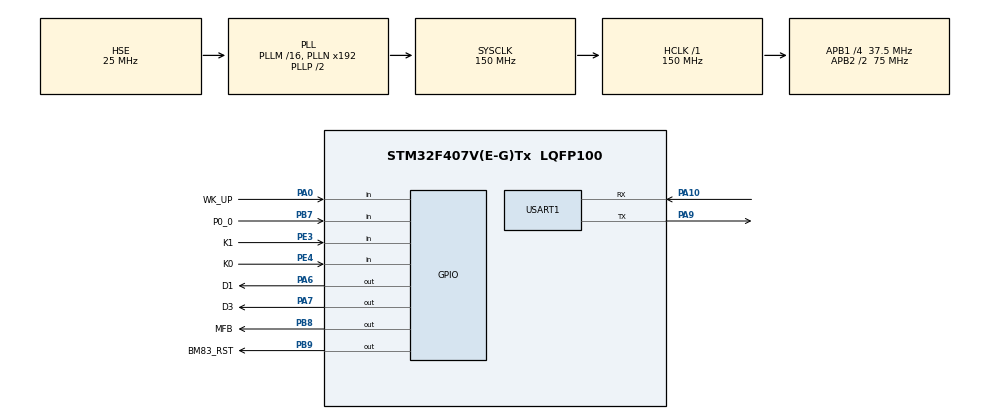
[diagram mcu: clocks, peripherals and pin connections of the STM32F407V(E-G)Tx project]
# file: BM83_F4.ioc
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Mcu.Family=STM32F4
Mcu.Name=STM32F407V(E-G)Tx
Mcu.Package=LQFP100
NVIC.PriorityGroup=NVIC_PRIORITYGROUP_4
NVIC.USART1_IRQn=true\:0\:0\:false\:false\:true\:true\:true\:true
PA0-WKUP.GPIO_Label=WK_UP
PA0-WKUP.Signal=GPIO_Input
PA10.Mode=Asynchronous
PA10.Signal=USART1_RX
PA13.Mode=JTAG_5_pins
PA13.Signal=SYS_JTMS-SWDIO
PA14.Mode=JTAG_5_pins
PA14.Signal=SYS_JTCK-SWCLK
PA15.Mode=JTAG_5_pins
PA15.Signal=SYS_JTDI
PA6.GPIO_Label=D1
PA6.Signal=GPIO_Output
PA7.GPIO_Label=D3
PA7.Signal=GPIO_Output
PA9.Mode=Asynchronous
PA9.Signal=USART1_TX
PB3.Mode=JTAG_5_pins
PB3.Signal=SYS_JTDO-SWO
PB4.Mode=JTAG_5_pins
PB4.Signal=SYS_JTRST
PB7.GPIO_Label=P0_0
PB7.Signal=GPIO_Input
PB8.GPIO_Label=MFB
PB8.Signal=GPIO_Output
PB9.GPIO_Label=BM83_RST
PB9.Signal=GPIO_Output
PC14-OSC32_IN.Mode=LSE-External-Oscillator
PC14-OSC32_IN.Signal=RCC_OSC32_IN
PC15-OSC32_OUT.Mode=LSE-External-Oscillator
PC15-OSC32_OUT.Signal=RCC_OSC32_OUT
PE3.GPIO_Label=K1
PE3.Signal=GPIO_Input
PE4.GPIO_Label=K0
PE4.Signal=GPIO_Input
PH0-OSC_IN.Mode=HSE-External-Oscillator
PH0-OSC_IN.Signal=RCC_OSC_IN
PH1-OSC_OUT.Mode=HSE-External-Oscillator
PH1-OSC_OUT.Signal=RCC_OSC_OUT
ProjectManager.HeapSize=0x200
ProjectManager.StackSize=0x400
ProjectManager.TargetToolchain=Makefile
RCC.48MHZClocksFreq_Value=75000000
RCC.AHBFreq_Value=150000000
RCC.APB1CLKDivider=RCC_HCLK_DIV4
RCC.APB1Freq_Value=37500000
RCC.APB1TimFreq_Value=75000000
RCC.APB2CLKDivider=RCC_HCLK_DIV2
RCC.APB2Freq_Value=75000000
RCC.APB2TimFreq_Value=150000000
RCC.CortexFreq_Value=150000000
RCC.HCLKFreq_Value=150000000
RCC.HSE_VALUE=25000000
RCC.HSI_VALUE=16000000
RCC.PLLSourceVirtual=RCC_PLLSOURCE_HSE
RCC.SYSCLKFreq_VALUE=150000000
RCC.SYSCLKSource=RCC_SYSCLKSOURCE_PLLCLK
RCC.VCOOutputFreq_Value=300000000
USART1.VirtualMode=VM_ASYNC
board=custom

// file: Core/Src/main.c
/* USER CODE BEGIN Header */
/**
  ******************************************************************************
  * @file           : main.c
  * @brief          : Main program body
  ******************************************************************************
  * @attention
  *
  * Copyright (c) 2024 STMicroelectronics.
  * All rights reserved.
  *
  * This software is licensed under terms that can be found in the LICENSE file
  * in the root directory of this software component.
  * If no LICENSE file comes with this software, it is provided AS-IS.
  *
  ******************************************************************************
  */
/* USER CODE END Header */
#include "main.h"
#include "app.h"
#include "app.c"

UART_HandleTypeDef huart1;

void SystemClock_Config(void);
static void MX_GPIO_Init(void);
static void MX_USART1_UART_Init(void);

int main(void)
{

  /* MCU Configuration--------------------------------------------------------*/

  /* Reset of all peripherals, Initializes the Flash interface and the Systick. */
  HAL_Init();

  /* Configure the system clock */
  SystemClock_Config();

  /* Initialize all configured peripherals */
  MX_GPIO_Init();
  MX_USART1_UART_Init();

  /* USER CODE BEGIN 2 */
  /*Initialize Bluetooth controller*/
  APP_Initialize();

  /* USER CODE END 2 */

  /* Infinite loop */
  while (1)
  {

  }
}

void SystemClock_Config(void)
{
  RCC_OscInitTypeDef RCC_OscInitStruct = {0};
  RCC_ClkInitTypeDef RCC_ClkInitStruct = {0};

  /** Configure the main internal regulator output voltage
  */
  __HAL_RCC_PWR_CLK_ENABLE();
  __HAL_PWR_VOLTAGESCALING_CONFIG(PWR_REGULATOR_VOLTAGE_SCALE1);

  /** Initializes the RCC Oscillators according to the specified parameters
  * in the RCC_OscInitTypeDef structure.
  */
  RCC_OscInitStruct.OscillatorType = RCC_OSCILLATORTYPE_HSE;
  RCC_OscInitStruct.HSEState = RCC_HSE_ON;
  RCC_OscInitStruct.PLL.PLLState = RCC_PLL_ON;
  RCC_OscInitStruct.PLL.PLLSource = RCC_PLLSOURCE_HSE;
  RCC_OscInitStruct.PLL.PLLM = 16;
  RCC_OscInitStruct.PLL.PLLN = 192;
  RCC_OscInitStruct.PLL.PLLP = RCC_PLLP_DIV2;
  RCC_OscInitStruct.PLL.PLLQ = 4;
  if (HAL_RCC_OscConfig(&RCC_OscInitStruct) != HAL_OK)
  {
    Error_Handler();
  }

  /** Initializes the CPU, AHB and APB buses clocks
  */
  RCC_ClkInitStruct.ClockType = RCC_CLOCKTYPE_HCLK|RCC_CLOCKTYPE_SYSCLK
                              |RCC_CLOCKTYPE_PCLK1|RCC_CLOCKTYPE_PCLK2;
  RCC_ClkInitStruct.SYSCLKSource = RCC_SYSCLKSOURCE_PLLCLK;
  RCC_ClkInitStruct.AHBCLKDivider = RCC_SYSCLK_DIV1;
  RCC_ClkInitStruct.APB1CLKDivider = RCC_HCLK_DIV4;
  RCC_ClkInitStruct.APB2CLKDivider = RCC_HCLK_DIV2;

  if (HAL_RCC_ClockConfig(&RCC_ClkInitStruct, FLASH_LATENCY_4) != HAL_OK)
  {
    Error_Handler();
  }
}

static void MX_USART1_UART_Init(void)
{

  /* USER CODE BEGIN USART1_Init 0 */
  // Enable one-bit sample method
  __HAL_UART_ONE_BIT_SAMPLE_ENABLE(&huart1);

  /* USER CODE END USART1_Init 0 */

  huart1.Instance = USART1;
  huart1.Init.BaudRate = 115200;
  huart1.Init.WordLength = UART_WORDLENGTH_8B;
  huart1.Init.StopBits = UART_STOPBITS_1;
  huart1.Init.Parity = UART_PARITY_NONE;
  huart1.Init.Mode = UART_MODE_TX_RX;
  huart1.Init.HwFlowCtl = UART_HWCONTROL_NONE;
  huart1.Init.OverSampling = UART_OVERSAMPLING_16;
  if (HAL_UART_Init(&huart1) != HAL_OK)
  {
    Error_Handler();
  }

}

static void MX_GPIO_Init(void)
{
  GPIO_InitTypeDef GPIO_InitStruct = {0};

  /* GPIO Ports Clock Enable */
  __HAL_RCC_GPIOE_CLK_ENABLE();
  __HAL_RCC_GPIOC_CLK_ENABLE();
  __HAL_RCC_GPIOH_CLK_ENABLE();
  __HAL_RCC_GPIOA_CLK_ENABLE();
  __HAL_RCC_GPIOB_CLK_ENABLE();

  /*Configure GPIO pin Output Level */
  HAL_GPIO_WritePin(GPIOA, D1_Pin|D3_Pin, GPIO_PIN_RESET);

  /*Configure GPIO pin Output Level */
  HAL_GPIO_WritePin(GPIOB, MFB_Pin|BM83_RST_Pin, GPIO_PIN_RESET);

  /*Configure GPIO pins : K1_Pin K0_Pin */
  GPIO_InitStruct.Pin = K1_Pin|K0_Pin;
  GPIO_InitStruct.Mode = GPIO_MODE_INPUT;
  GPIO_InitStruct.Pull = GPIO_NOPULL;
  HAL_GPIO_Init(GPIOE, &GPIO_InitStruct);

  /*Configure GPIO pin : WK_UP_Pin */
  GPIO_InitStruct.Pin = WK_UP_Pin;
  GPIO_InitStruct.Mode = GPIO_MODE_INPUT;
  GPIO_InitStruct.Pull = GPIO_NOPULL;
  HAL_GPIO_Init(WK_UP_GPIO_Port, &GPIO_InitStruct);

  /*Configure GPIO pins : D1_Pin D3_Pin */
  GPIO_InitStruct.Pin = D1_Pin|D3_Pin;
  GPIO_InitStruct.Mode = GPIO_MODE_OUTPUT_PP;
  GPIO_InitStruct.Pull = GPIO_NOPULL;
  GPIO_InitStruct.Speed = GPIO_SPEED_FREQ_LOW;
  HAL_GPIO_Init(GPIOA, &GPIO_InitStruct);

  /*Configure GPIO pin : P0_0_Pin */
  GPIO_InitStruct.Pin = P0_0_Pin;
  GPIO_InitStruct.Mode = GPIO_MODE_INPUT;
  GPIO_InitStruct.Pull = GPIO_NOPULL;
  HAL_GPIO_Init(P0_0_GPIO_Port, &GPIO_InitStruct);

  /*Configure GPIO pins : MFB_Pin BM83_RST_Pin */
  GPIO_InitStruct.Pin = MFB_Pin|BM83_RST_Pin;
  GPIO_InitStruct.Mode = GPIO_MODE_OUTPUT_PP;
  GPIO_InitStruct.Pull = GPIO_NOPULL;
  GPIO_InitStruct.Speed = GPIO_SPEED_FREQ_LOW;
  HAL_GPIO_Init(GPIOB, &GPIO_InitStruct);

}

void Error_Handler(void)
{
  __disable_irq();
  while (1)
  {
  }
}
